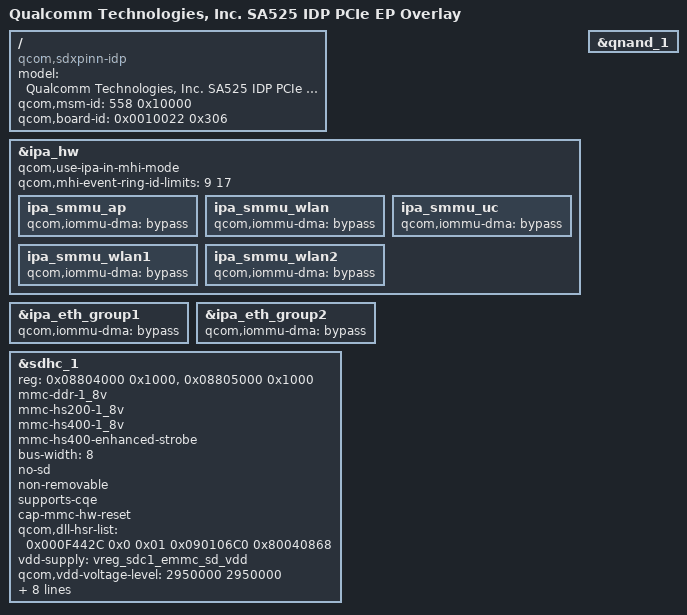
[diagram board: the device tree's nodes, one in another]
/dts-v1/;
/plugin/;

#include "sa525m-idp.dtsi"

/ {
	model = "Qualcomm Technologies, Inc. SA525 IDP PCIe EP Overlay";
	compatible = "qcom,sdxpinn-idp",
		"qcom,sdxpinn", "qcom,idp";
	qcom,msm-id=<558 0x10000>;
	qcom,board-id = <0x0010022 0x306>;
};

&ipa_hw {
	qcom,use-ipa-in-mhi-mode;
	qcom,mhi-event-ring-id-limits = <9 17>;

	ipa_smmu_ap: ipa_smmu_ap {
		qcom,iommu-dma = "bypass";
	};

	ipa_smmu_wlan: ipa_smmu_wlan {
		qcom,iommu-dma = "bypass";
	};

	ipa_smmu_uc: ipa_smmu_uc {
		qcom,iommu-dma = "bypass";
	};

	ipa_smmu_wlan1: ipa_smmu_wlan1 {
		qcom,iommu-dma = "bypass";
	};

	ipa_smmu_wlan2: ipa_smmu_wlan2 {
		qcom,iommu-dma = "bypass";
	};
};

&ipa_eth_group1 {
	qcom,iommu-dma = "bypass";
};

&ipa_eth_group2 {
	qcom,iommu-dma = "bypass";
};

&qnand_1 {
	status = "ok";
};

&sdhc_1 {
	status = "ok";

	reg = <0x08804000 0x1000>, <0x08805000 0x1000>;
	reg-names = "hc", "cqhci";

	mmc-ddr-1_8v;
	mmc-hs200-1_8v;
	mmc-hs400-1_8v;
	mmc-hs400-enhanced-strobe;

	bus-width = <8>;
	no-sd;
	non-removable;
	supports-cqe;
	cap-mmc-hw-reset;

	/* DLL HSR settings. Refer go/hsr - <Target> DLL settings */
	qcom,dll-hsr-list = <0x000F442C 0x0 0x01
				0x090106C0 0x80040868>;

	vdd-supply = <&vreg_sdc1_emmc_sd_vdd>;
	qcom,vdd-voltage-level = <2950000 2950000>;
	qcom,vdd-current-level = <0 570000>;

	vdd-io-supply = <&L6B>;
	qcom,vdd-io-always-on;
	qcom,vdd-io-lpm-sup;
	qcom,vdd-io-voltage-level = <1800000 1800000>;
	qcom,vdd-io-current-level = <0 200000>;

	pinctrl-names = "default", "sleep";
	pinctrl-0 = <&sdc1_emmc_on>;
	pinctrl-1 = <&sdc1_emmc_off>;
};

#include "sa525m-ep.dtsi"
